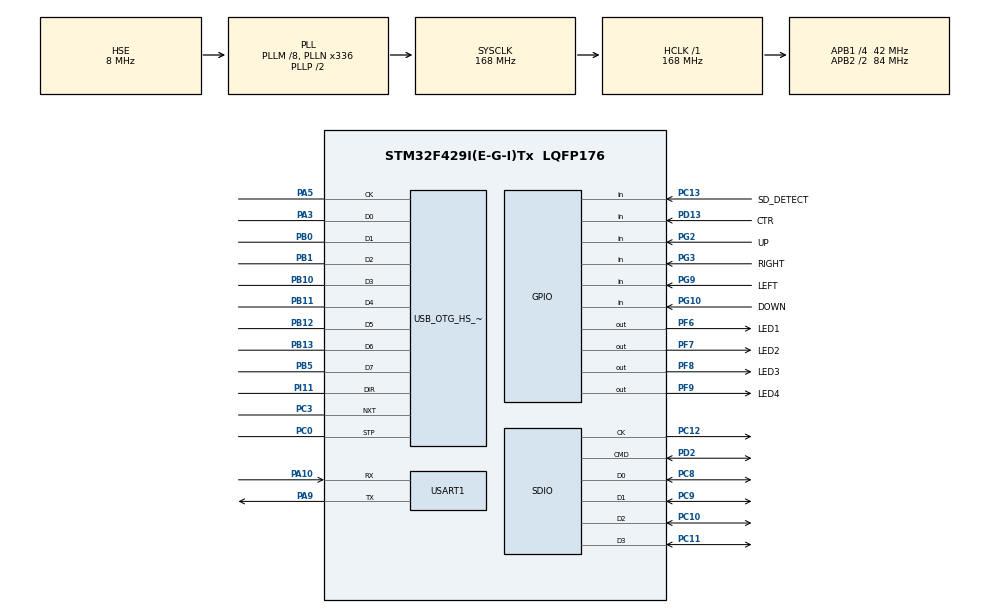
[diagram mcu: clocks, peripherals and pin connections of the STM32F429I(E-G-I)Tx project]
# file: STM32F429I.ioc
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Dma.MEMTOMEM.0.Channel=DMA_CHANNEL_0
Dma.MEMTOMEM.0.Direction=DMA_MEMORY_TO_MEMORY
Dma.MEMTOMEM.0.FIFOMode=DMA_FIFOMODE_ENABLE
Dma.MEMTOMEM.0.FIFOThreshold=DMA_FIFO_THRESHOLD_FULL
Dma.MEMTOMEM.0.Instance=DMA2_Stream0
Dma.MEMTOMEM.0.MemBurst=DMA_MBURST_SINGLE
Dma.MEMTOMEM.0.MemDataAlignment=DMA_MDATAALIGN_WORD
Dma.MEMTOMEM.0.MemInc=DMA_MINC_ENABLE
Dma.MEMTOMEM.0.Mode=DMA_NORMAL
Dma.MEMTOMEM.0.PeriphBurst=DMA_PBURST_SINGLE
Dma.MEMTOMEM.0.PeriphDataAlignment=DMA_PDATAALIGN_WORD
Dma.MEMTOMEM.0.PeriphInc=DMA_PINC_ENABLE
Dma.MEMTOMEM.0.Priority=DMA_PRIORITY_LOW
Dma.Request0=MEMTOMEM
Dma.Request1=SDIO_RX
Dma.Request2=SDIO_TX
Dma.SDIO_RX.1.Channel=DMA_CHANNEL_4
Dma.SDIO_RX.1.Direction=DMA_PERIPH_TO_MEMORY
Dma.SDIO_RX.1.FIFOMode=DMA_FIFOMODE_ENABLE
Dma.SDIO_RX.1.FIFOThreshold=DMA_FIFO_THRESHOLD_FULL
Dma.SDIO_RX.1.Instance=DMA2_Stream3
Dma.SDIO_RX.1.MemBurst=DMA_MBURST_INC4
Dma.SDIO_RX.1.MemDataAlignment=DMA_MDATAALIGN_WORD
Dma.SDIO_RX.1.MemInc=DMA_MINC_ENABLE
Dma.SDIO_RX.1.Mode=DMA_PFCTRL
Dma.SDIO_RX.1.PeriphBurst=DMA_PBURST_INC4
Dma.SDIO_RX.1.PeriphDataAlignment=DMA_PDATAALIGN_WORD
Dma.SDIO_RX.1.PeriphInc=DMA_PINC_DISABLE
Dma.SDIO_RX.1.Priority=DMA_PRIORITY_LOW
Dma.SDIO_TX.2.Channel=DMA_CHANNEL_4
Dma.SDIO_TX.2.Direction=DMA_MEMORY_TO_PERIPH
Dma.SDIO_TX.2.FIFOMode=DMA_FIFOMODE_ENABLE
Dma.SDIO_TX.2.FIFOThreshold=DMA_FIFO_THRESHOLD_FULL
Dma.SDIO_TX.2.Instance=DMA2_Stream6
Dma.SDIO_TX.2.MemBurst=DMA_MBURST_INC4
Dma.SDIO_TX.2.MemDataAlignment=DMA_MDATAALIGN_WORD
Dma.SDIO_TX.2.MemInc=DMA_MINC_ENABLE
Dma.SDIO_TX.2.Mode=DMA_PFCTRL
Dma.SDIO_TX.2.PeriphBurst=DMA_PBURST_INC4
Dma.SDIO_TX.2.PeriphDataAlignment=DMA_PDATAALIGN_WORD
Dma.SDIO_TX.2.PeriphInc=DMA_PINC_DISABLE
Dma.SDIO_TX.2.Priority=DMA_PRIORITY_LOW
FATFS._CODE_PAGE=936
Mcu.Family=STM32F4
Mcu.Name=STM32F429I(E-G-I)Tx
Mcu.Package=LQFP176
NVIC.DMA2_Stream3_IRQn=true\:6\:0\:true
NVIC.DMA2_Stream6_IRQn=true\:6\:0\:true
NVIC.OTG_HS_IRQn=true\:7\:0\:true
NVIC.PriorityGroup=NVIC_PRIORITYGROUP_4
NVIC.SDIO_IRQn=true\:5\:0\:true
PA10.Mode=Asynchronous
PA10.Signal=USART1_RX
PA3.Mode=Host_HS
PA3.Signal=USB_OTG_HS_ULPI_D0
PA5.Mode=Host_HS
PA5.Signal=USB_OTG_HS_ULPI_CK
PA9.Mode=Asynchronous
PA9.Signal=USART1_TX
PB0.Mode=Host_HS
PB0.Signal=USB_OTG_HS_ULPI_D1
PB1.Mode=Host_HS
PB1.Signal=USB_OTG_HS_ULPI_D2
PB10.Mode=Host_HS
PB10.Signal=USB_OTG_HS_ULPI_D3
PB11.Mode=Host_HS
PB11.Signal=USB_OTG_HS_ULPI_D4
PB12.Mode=Host_HS
PB12.Signal=USB_OTG_HS_ULPI_D5
PB13.Mode=Host_HS
PB13.Signal=USB_OTG_HS_ULPI_D6
PB5.Mode=Host_HS
PB5.Signal=USB_OTG_HS_ULPI_D7
PC0.Mode=Host_HS
PC0.Signal=USB_OTG_HS_ULPI_STP
PC10.GPIO_PuPd=GPIO_PULLUP
PC10.Mode=SD_4_bits_Wide_bus
PC10.Signal=SDIO_D2
PC11.GPIO_PuPd=GPIO_PULLUP
PC11.Mode=SD_4_bits_Wide_bus
PC11.Signal=SDIO_D3
PC12.Mode=SD_4_bits_Wide_bus
PC12.Signal=SDIO_CK
PC13.GPIO_Label=SD_DETECT
PC13.Signal=GPIO_Input
PC3.Mode=Host_HS
PC3.Signal=USB_OTG_HS_ULPI_NXT
PC8.GPIO_PuPd=GPIO_PULLUP
PC8.Mode=SD_4_bits_Wide_bus
PC8.Signal=SDIO_D0
PC9.GPIO_PuPd=GPIO_PULLUP
PC9.Mode=SD_4_bits_Wide_bus
PC9.Signal=SDIO_D1
PD13.GPIO_Label=CTR
PD13.GPIO_PuPd=GPIO_PULLUP
PD13.Signal=GPIO_Input
PD2.GPIO_PuPd=GPIO_PULLUP
PD2.Mode=SD_4_bits_Wide_bus
PD2.Signal=SDIO_CMD
PF6.GPIO_Label=LED1
PF6.Signal=GPIO_Output
PF7.GPIO_Label=LED2
PF7.Signal=GPIO_Output
PF8.GPIO_Label=LED3
PF8.Signal=GPIO_Output
PF9.GPIO_Label=LED4
PF9.Signal=GPIO_Output
PG10.GPIO_Label=DOWN
PG10.GPIO_PuPd=GPIO_PULLUP
PG10.Signal=GPIO_Input
PG2.GPIO_Label=UP
PG2.GPIO_PuPd=GPIO_PULLUP
PG2.Signal=GPIO_Input
PG3.GPIO_Label=RIGHT
PG3.GPIO_PuPd=GPIO_PULLUP
PG3.Signal=GPIO_Input
PG9.GPIO_Label=LEFT
PG9.GPIO_PuPd=GPIO_PULLUP
PG9.Signal=GPIO_Input
PH0/OSC_IN.Mode=HSE-External-Oscillator
PH0/OSC_IN.Signal=RCC_OSC_IN
PH1/OSC_OUT.Mode=HSE-External-Oscillator
PH1/OSC_OUT.Signal=RCC_OSC_OUT
PI11.Mode=Host_HS
PI11.Signal=USB_OTG_HS_ULPI_DIR
ProjectManager.TargetToolchain=MDK-ARM V5
RCC.48MHZClocksFreq_Value=48000000
RCC.AHBFreq_Value=168000000
RCC.APB1CLKDivider=RCC_HCLK_DIV4
RCC.APB1Freq_Value=42000000
RCC.APB1TimFreq_Value=84000000
RCC.APB2CLKDivider=RCC_HCLK_DIV2
RCC.APB2Freq_Value=84000000
RCC.APB2TimFreq_Value=168000000
RCC.CortexFreq_Value=168000000
RCC.HCLKFreq_Value=168000000
RCC.HSE_VALUE=8000000
RCC.HSI_VALUE=16000000
RCC.LSE_VALUE=32768
RCC.PLLM=8
RCC.PLLN=336
RCC.PLLQ=7
RCC.PLLSAIN=192
RCC.PLLSAIR=3
RCC.PLLSourceVirtual=RCC_PLLSOURCE_HSE
RCC.SYSCLKFreq_VALUE=168000000
RCC.SYSCLKSource=RCC_SYSCLKSOURCE_PLLCLK
RCC.VCOOutputFreq_Value=336000000
SDIO.BusWide=SDIO_BUS_WIDE_1B
SDIO.WideMode=SDIO_BUS_WIDE_4B
USB_HOST.USBH_DEBUG_LEVEL-MSC_HS=2
USB_HOST.USBH_HandleTypeDef-MSC_HS=hUsbHostHS
USB_HOST.USBH_MAX_DATA_BUFFER-MSC_HS=0x200
USB_HOST.USBH_MAX_SIZE_CONFIGURATION-MSC_HS=0x200
USB_HOST.VirtualModeHS=Msc
USB_OTG_HS.speed-Host_HS=HCD_SPEED_FULL
VP_FATFS_VS_USB.Mode=USB
VP_USB_HOST_VS_USB_HOST_MSC_HS.Mode=MSC_HS
board=STM32F429I

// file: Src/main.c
/**
  ******************************************************************************
  * File Name          : main.c
  * Description        : Main program body
  ******************************************************************************
  *
  * COPYRIGHT(c) 2015 STMicroelectronics
  *
  * Redistribution and use in source and binary forms, with or without modification,
  * are permitted provided that the following conditions are met:
  *   1. Redistributions of source code must retain the above copyright notice,
  *      this list of conditions and the following disclaimer.
  *   2. Redistributions in binary form must reproduce the above copyright notice,
  *      this list of conditions and the following disclaimer in the documentation
  *      and/or other materials provided with the distribution.
  *   3. Neither the name of STMicroelectronics nor the names of its contributors
  *      may be used to endorse or promote products derived from this software
  *      without specific prior written permission.
  *
  * THIS SOFTWARE IS PROVIDED BY THE COPYRIGHT HOLDERS AND CONTRIBUTORS "AS IS"
  * AND ANY EXPRESS OR IMPLIED WARRANTIES, INCLUDING, BUT NOT LIMITED TO, THE
  * IMPLIED WARRANTIES OF MERCHANTABILITY AND FITNESS FOR A PARTICULAR PURPOSE ARE
  * DISCLAIMED. IN NO EVENT SHALL THE COPYRIGHT HOLDER OR CONTRIBUTORS BE LIABLE
  * FOR ANY DIRECT, INDIRECT, INCIDENTAL, SPECIAL, EXEMPLARY, OR CONSEQUENTIAL
  * DAMAGES (INCLUDING, BUT NOT LIMITED TO, PROCUREMENT OF SUBSTITUTE GOODS OR
  * SERVICES; LOSS OF USE, DATA, OR PROFITS; OR BUSINESS INTERRUPTION) HOWEVER
  * CAUSED AND ON ANY THEORY OF LIABILITY, WHETHER IN CONTRACT, STRICT LIABILITY,
  * OR TORT (INCLUDING NEGLIGENCE OR OTHERWISE) ARISING IN ANY WAY OUT OF THE USE
  * OF THIS SOFTWARE, EVEN IF ADVISED OF THE POSSIBILITY OF SUCH DAMAGE.
  *
  ******************************************************************************
  */
#include "stm32f4xx_hal.h"
#include "dma.h"
#include "fatfs.h"
#include "sdio.h"
#include "usart.h"
#include "usb_host.h"
#include "gpio.h"

/* USER CODE BEGIN PV */
/* Private variables ---------------------------------------------------------*/
extern FATFS USBH_fatfs;
/* USER CODE END PV */

void SystemClock_Config(void);
void MX_USB_HOST_Process(void);

/* USER CODE BEGIN PFP */
/* Private function prototypes -----------------------------------------------*/
extern void Menu_Init(void);
extern void MSC_MenuProcess(void);
/* USER CODE END PFP */

int main(void)
{

  /* MCU Configuration----------------------------------------------------------*/

  /* Reset of all peripherals, Initializes the Flash interface and the Systick. */
  HAL_Init();

  /* Configure the system clock */
  SystemClock_Config();

  /* Initialize all configured peripherals */
  MX_GPIO_Init();
  MX_DMA_Init();
  MX_SDIO_SD_Init();
  MX_USART1_UART_Init();
  MX_FATFS_Init();
  MX_USB_HOST_Init();

  /* USER CODE BEGIN 2 */
	printf(" USB OTG FS MSC Host\r\n");
  printf("WaveShare Open7XXI-C board\r\n");
	printf("USB Host library started.\r\n");

	/* Register the file system object to the FatFs module */
	if(f_mount(&USBH_fatfs, "", 0) != FR_OK)
  {
    printf("Cannot Initialize FatFs! \r\n");
  }

	/* Initialize menu and MSC process */
  Menu_Init();
  /* USER CODE END 2 */

  /* Infinite loop */
  while (1)
  {
    MX_USB_HOST_Process();

  /* USER CODE BEGIN 3 */
		/* MSC Menu Process */
    MSC_MenuProcess();
  }
  /* USER CODE END 3 */

}

/** System Clock Configuration
*/
void SystemClock_Config(void)
{

  RCC_OscInitTypeDef RCC_OscInitStruct;
  RCC_ClkInitTypeDef RCC_ClkInitStruct;

  __PWR_CLK_ENABLE();

  __HAL_PWR_VOLTAGESCALING_CONFIG(PWR_REGULATOR_VOLTAGE_SCALE1);

  RCC_OscInitStruct.OscillatorType = RCC_OSCILLATORTYPE_HSE;
  RCC_OscInitStruct.HSEState = RCC_HSE_ON;
  RCC_OscInitStruct.PLL.PLLState = RCC_PLL_ON;
  RCC_OscInitStruct.PLL.PLLSource = RCC_PLLSOURCE_HSE;
  RCC_OscInitStruct.PLL.PLLM = 8;
  RCC_OscInitStruct.PLL.PLLN = 336;
  RCC_OscInitStruct.PLL.PLLP = RCC_PLLP_DIV2;
  RCC_OscInitStruct.PLL.PLLQ = 7;
  HAL_RCC_OscConfig(&RCC_OscInitStruct);

  RCC_ClkInitStruct.ClockType = RCC_CLOCKTYPE_SYSCLK|RCC_CLOCKTYPE_PCLK1
                              |RCC_CLOCKTYPE_PCLK2;
  RCC_ClkInitStruct.SYSCLKSource = RCC_SYSCLKSOURCE_PLLCLK;
  RCC_ClkInitStruct.AHBCLKDivider = RCC_SYSCLK_DIV1;
  RCC_ClkInitStruct.APB1CLKDivider = RCC_HCLK_DIV4;
  RCC_ClkInitStruct.APB2CLKDivider = RCC_HCLK_DIV2;
  HAL_RCC_ClockConfig(&RCC_ClkInitStruct, FLASH_LATENCY_5);

  HAL_SYSTICK_Config(HAL_RCC_GetHCLKFreq()/1000);

  HAL_SYSTICK_CLKSourceConfig(SYSTICK_CLKSOURCE_HCLK);

  /* SysTick_IRQn interrupt configuration */
  HAL_NVIC_SetPriority(SysTick_IRQn, 0, 0);
}

/************************ (C) COPYRIGHT STMicroelectronics *****END OF FILE****/
